# LPC5411x register map
Vendor: nxp.com; File version: 1.2
CPU: CM4 r0p1, little endian, MPU, FPU, VTOR, vendor SysTick, 3 interrupt priority bits
Registers are 32-bit, read-write, reset 0x0 unless marked. A register's access mark holds for its fields unless they carry their own. Offsets are from the block's base; [hi:lo] are bit positions; {n}, {i} and the like mark numbered series; 'fields as' and 'values as' point back to an identical list.

## SYSCON — LPC5411x System configuration (SYSCON)
Base 0x40000000
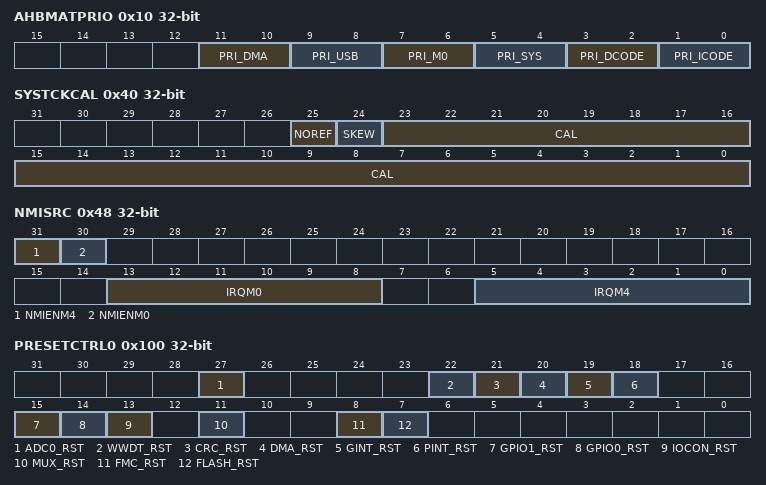
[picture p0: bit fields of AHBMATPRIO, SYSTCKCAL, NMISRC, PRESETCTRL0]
0x10 AHBMATPRIO — AHB multilayer matrix priority control
  [11:10] PRI_DMA — DMA controller priority.
  [9:8] PRI_USB — USB interface priority.
  [7:6] PRI_M0 — Cortex-M0+ bus priority. Present on selected devices.
  [5:4] PRI_SYS — Cortex M4 System bus priority.
  [3:2] PRI_DCODE — Cortex M4 D-Code bus priority.
  [1:0] PRI_ICODE — Cortex-M4 I-Code bus priority. Should typically be lower than PRI_DCODE for best operation.
0x40 SYSTCKCAL — System tick counter calibration
  [25] NOREF — Initial value for the Systick timer.
  [24] SKEW — Initial value for the Systick timer.
  [23:0] CAL — System tick timer calibration value.
0x48 NMISRC — NMI Source Select
  [31] NMIENM4 — Write a 1 to this bit to enable the Non-Maskable Interrupt (NMI) source selected by IRQM4.
  [30] NMIENM0 — Write a 1 to this bit to enable the Non-Maskable Interrupt (NMI) source selected by IRQM0. Present on selected devices.
  [13:8] IRQM0 — The IRQ number of the interrupt that acts as the Non-Maskable Interrupt (NMI) for the Cortex-M0+, if enabled by NMIENM0. Present on selected devices.
  [5:0] IRQM4 — The IRQ number of the interrupt that acts as the Non-Maskable Interrupt (NMI) for the Cortex-M4, if enabled by NMIENM4.
0x4C ASYNCAPBCTRL reset 0x1 — Asynchronous APB Control
  [0] ENABLE — Enables the asynchronous APB bridge and subsystem.
    0=DISABLED (Disabled. Asynchronous APB bridge is disabled.); 1=ENABLED (Enabled. Asynchronous APB bridge is enabled.)
0xC0 PIOPORCAP0 — POR captured value of port 0
  [31:0] PIOPORCAP ro — State of PIO0_31 through PIO0_0 at power-on reset
0xC4 PIOPORCAP1 — POR captured value of port 1
  [31:0] PIOPORCAP ro — State of PIO1_31 through PIO1_0 at power-on reset
0xD0 PIORESCAP0 — Reset captured value of port 0
  [31:0] PIORESCAP ro — State of PIO0_31 through PIO0_0 for resets other than POR.
0xD4 PIORESCAP1 — Reset captured value of port 1
  [31:0] PIORESCAP ro — State of PIO1_31 through PIO1_0 for resets other than POR.
0x100 PRESETCTRL0 — Peripheral reset control 0
  [27] ADC0_RST — ADC0 reset control. 0 = Clear reset to this function. 1 = Assert reset to this function.
  [22] WWDT_RST — Watchdog timer reset control. 0 = Clear reset to this function. 1 = Assert reset to this function.
  [21] CRC_RST — CRC generator reset control. 0 = Clear reset to this function. 1 = Assert reset to this function.
  [20] DMA_RST — DMA reset control. 0 = Clear reset to this function. 1 = Assert reset to this function.
  [19] GINT_RST — Grouped interrupt (GINT) reset control. 0 = Clear reset to this function. 1 = Assert reset to this function.
  [18] PINT_RST — Pin interrupt (PINT) reset control. 0 = Clear reset to this function. 1 = Assert reset to this function.
  [15] GPIO1_RST — GPIO1 reset control. 0 = Clear reset to this function. 1 = Assert reset to this function.
  [14] GPIO0_RST — GPIO0 reset control. 0 = Clear reset to this function. 1 = Assert reset to this function.
  [13] IOCON_RST — IOCON reset control. 0 = Clear reset to this function. 1 = Assert reset to this function.
  [11] MUX_RST — Input mux reset control. 0 = Clear reset to this function. 1 = Assert reset to this function.
  [8] FMC_RST — Flash accelerator reset control. Note that the FMC must not be reset while executing from flash, and must be reconfigured after reset. 0 = Clear reset to this function. 1 = Assert reset to this function.
  [7] FLASH_RST — Flash controller reset control. 0 = Clear reset to this function. 1 = Assert reset to this function.
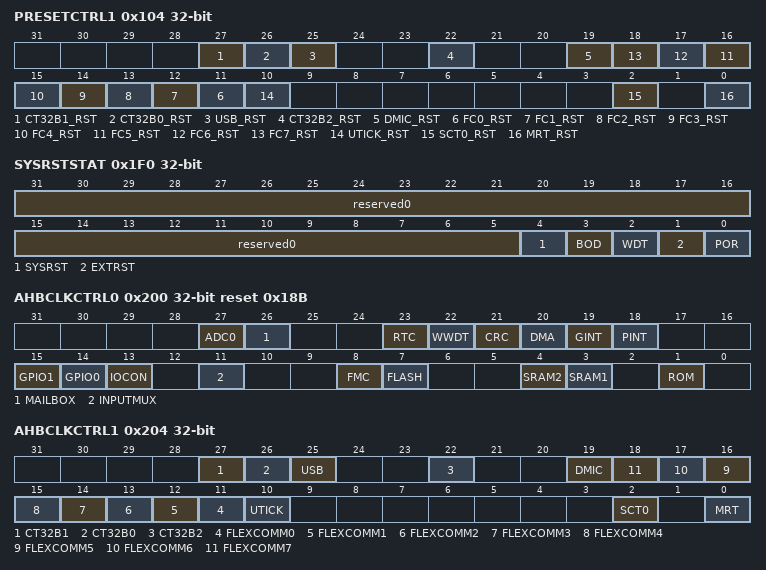
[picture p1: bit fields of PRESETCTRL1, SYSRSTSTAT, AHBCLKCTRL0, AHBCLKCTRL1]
0x104 PRESETCTRL1 — Peripheral reset control 1
  [27] CT32B1_RST — CT32B1 reset control. 0 = Clear reset to this function. 1 = Assert reset to this function.
  [26] CT32B0_RST — CT32B0 reset control. 0 = Clear reset to this function. 1 = Assert reset to this function.
  [25] USB_RST — USB reset control. 0 = Clear reset to this function. 1 = Assert reset to this function.
  [22] CT32B2_RST — CT32B2 reset control. 0 = Clear reset to this function. 1 = Assert reset to this function
  [19] DMIC_RST — Digital microphone interface reset control. 0 = Clear reset to this function. 1 = Assert reset to this function.
  [n+11] FC{n}_RST (n=0..7) — Flexcomm {n} reset control. 0 = Clear reset to this function. 1 = Assert reset to this function.
  [10] UTICK_RST — Micro-tick Timer reset control. 0 = Clear reset to this function. 1 = Assert reset to this function.
  [2] SCT0_RST — State configurable timer 0 (SCT0) reset control. 0 = Clear reset to this function. 1 = Assert reset to this function.
  [0] MRT_RST — Multi-rate timer (MRT) reset control. 0 = Clear reset to this function. 1 = Assert reset to this function.
0x120 PRESETCTRLSET0 reset not defined — Set bits in PRESETCTRL0
  [31:0] RST_SET0 wo — Writing ones to this register sets the corresponding bit or bits in the PRESETCTRL0 register, if they are implemented. Bits that do not correspond to defined bits in PRESETCTRL0 are reserved and only zeroes should be written to them.
0x124 PRESETCTRLSET1 reset not defined — Set bits in PRESETCTRL1
  [31:0] RST_SET1 wo — Writing ones to this register sets the corresponding bit or bits in the PRESETCTRL1 register, if they are implemented. Bits that do not correspond to defined bits in PRESETCTRL1 are reserved and only zeroes should be written to them.
0x140 PRESETCTRLCLR0 reset not defined — Clear bits in PRESETCTRL0
  [31:0] RST_CLR0 wo — Writing ones to this register clears the corresponding bit or bits in the PRESETCTRL0 register, if they are implemented. Bits that do not correspond to defined bits in PRESETCTRL0 are reserved and only zeroes should be written to them.
0x144 PRESETCTRLCLR1 reset not defined — Clear bits in PRESETCTRL1
  [31:0] RST_CLR1 wo — Writing ones to this register clears the corresponding bit or bits in the PRESETCTRL1 register, if they are implemented. Bits that do not correspond to defined bits in PRESETCTRL1 are reserved and only zeroes should be written to them.
0x1F0 SYSRSTSTAT (reset mask 0x1F) — System reset status register
  [31:5] reserved0 wo
  [4] SYSRST — Status of the software system reset
    0=NO_SYSTEM_RESET_DETECTED; 1=SYSTEM_RESET_DETECTED (System reset detected. Writing a one clears this reset.)
  [3] BOD — Status of the Brown-out detect reset
    0=NO_BOD_RESET_DETECTED; 1=BOD_RESET_DETECTED (BOD reset detected. Writing a one clears this reset.)
  [2] WDT — Status of the Watchdog reset
    0=NO_WDT_RESET_DETECTED; 1=WDT_RESET_DETECTED (WDT reset detected. Writing a one clears this reset.)
  [1] EXTRST — Status of the external RESET pin. External reset status
    0=NO_RESET_DETECTED (No reset event detected.); 1=RESET_DETECTED (Reset detected. Writing a one clears this reset.)
  [0] POR — POR reset status
    0=NO_POR_DETECTED; 1=POR_DETECTED (POR detected. Writing a one clears this reset.)
0x200 AHBCLKCTRL0 reset 0x18B — AHB Clock control 0
  [27] ADC0 — Enables the clock for the ADC0 register interface. 0 = Disable; 1 = Enable.
  [26] MAILBOX — Enables the clock for the Mailbox. 0 = Disable; 1 = Enable. Present on selected devices
  [23] RTC — Enables the bus clock for the RTC. 0 = Disable; 1 = Enable.
  [22] WWDT — Enables the clock for the Watchdog Timer. 0 = Disable; 1 = Enable.
  [21] CRC — Enables the clock for the CRC engine. 0 = Disable; 1 = Enable.
  [20] DMA — Enables the clock for the DMA controller. 0 = Disable; 1 = Enable.
  [19] GINT — Enables the clock for the grouped pin interrupt block. 0 = Disable; 1 = Enable.
  [18] PINT — Enables the clock for the pin interrupt block.0 = Disable; 1 = Enable.
  [15] GPIO1 — Enables the clock for the GPIO1 port registers. 0 = Disable; 1 = Enable.
  [14] GPIO0 — Enables the clock for the GPIO0 port registers. 0 = Disable; 1 = Enable.
  [13] IOCON — Enables the clock for the IOCON block. 0 = Disable; 1 = Enable.
  [11] INPUTMUX — Enables the clock for the input muxes. 0 = Disable; 1 = Enable.
  [8] FMC — Enables the clock for the Flash accelerator. 0 = Disable; 1 = Enable. This clock is needed if the flash is being read.
  [7] FLASH — Enables the clock for the flash controller. 0 = Disable; 1 = Enable. This clock is needed for flash programming, not for flash read.
  [4] SRAM2 — Enables the clock for SRAM2. 0 = Disable; 1 = Enable.
  [3] SRAM1 — Enables the clock for SRAM1. 0 = Disable; 1 = Enable.
  [1] ROM — Enables the clock for the Boot ROM. 0 = Disable; 1 = Enable.
0x204 AHBCLKCTRL1 — AHB Clock control 1
  [27] CT32B1 — Enables the clock for timer CT32B1. 0 = Disable; 1 = Enable.
  [26] CT32B0 — Enables the clock for timer CT32B0. 0 = Disable; 1 = Enable.
  [25] USB — Enables the clock for the USB interface. 0 = Disable; 1 = Enable.
  [22] CT32B2 — Enables the clock for CT32B 2. 0 = Disable; 1 = Enable.
  [19] DMIC — Enables the clock for the digital microphone interface. 0 = Disable; 1 = Enable.
  [n+11] FLEXCOMM{n} (n=0..7) — Enables the clock for Flexcomm {n}. 0 = Disable; 1 = Enable.
  [10] UTICK — Enables the clock for the Micro-tick Timer. 0 = Disable; 1 = Enable.
  [2] SCT0 — Enables the clock for SCT0. 0 = Disable; 1 = Enable.
  [0] MRT — Enables the clock for the Multi-Rate Timer. 0 = Disable; 1 = Enable.
0x220 AHBCLKCTRLSET0 reset not defined — Set bits in AHBCLKCTRL0
  [31:0] CLK_SET0 wo — Writing ones to this register sets the corresponding bit or bits in the AHBCLKCTRL0 register, if they are implemented. Bits that do not correspond to defined bits in AHBCLKCTRL0 are reserved and only zeroes should be written to them.
0x224 AHBCLKCTRLSET1 reset not defined — Set bits in AHBCLKCTRL1
  [31:0] CLK_SET1 wo — Writing ones to this register sets the corresponding bit or bits in the AHBCLKCTRL1 register, if they are implemented. Bits that do not correspond to defined bits in AHBCLKCTRL1 are reserved and only zeroes should be written to them.
0x240 AHBCLKCTRLCLR0 reset not defined — Clear bits in AHBCLKCTRL0
  [31:0] CLK_CLR0 wo — Writing ones to this register clears the corresponding bit or bits in the AHBCLKCTRL0 register, if they are implemented. Bits that do not correspond to defined bits in AHBCLKCTRL0 are reserved and only zeroes should be written to them.
0x244 AHBCLKCTRLCLR1 reset not defined — Clear bits in AHBCLKCTRL1
  [31:0] CLK_CLR1 wo — Writing ones to this register clears the corresponding bit or bits in the AHBCLKCTRL1 register, if they are implemented. Bits that do not correspond to defined bits in AHBCLKCTRL1 are reserved and only zeroes should be written to them.
0x280 MAINCLKSELA — Main clock source select A
  [1:0] SEL — Clock source for main clock source selector A
    0=FRO_12_MHZ (FRO 12 MHz (fro_12m)); 1=CLKIN (CLKIN (clk_in)); 2=WATCHDOG_OSCILLATOR (Watchdog oscillator (wdt_clk)); 3=FRO_HF (FRO 96 or 48 MHz (fro_hf))
0x284 MAINCLKSELB — Main clock source select B
  [1:0] SEL — Clock source for main clock source selector B. Selects the clock source for the main clock.
    0=MAINCLKSELA (MAINCLKSELA. Use the clock source selected in MAINCLKSELA register.); 2=SYSTEM_PLL_OUTPUT (System PLL output (pll_clk)); 3=RTC_OSC_OUTPUT (RTC oscillator 32 kHz output (32k_clk))
0x288 CLKOUTSELA reset 0x7 — CLKOUT clock source select A
  [2:0] SEL — CLKOUT clock source selection
    0=MAIN_CLOCK (Main clock (main_clk)); 1=CLKIN (CLKIN (clk_in)); 2=WATCHDOG_OSCILLATOR (Watchdog oscillator (wdt_clk)); 3=FRO_HF (FRO 96 or 48 MHz (fro_hf)); 4=SYSTEM_PLL_OUTPUT (PLL output (pll_clk)); 5=FRO_12_MHZ (FRO 12 MHz (fro_12m)); 6=RTC_OSC_OUTPUT (RTC oscillator 32 kHz output (32k_clk)); 7=NONE (None, this may be selected in order to reduce power when no output is needed.)
0x290 SYSPLLCLKSEL reset 0x7 — PLL clock source select
  [2:0] SEL — System PLL clock source selection
    0=FRO_12_MHZ (FRO 12 MHz (fro_12m)); 1=CLKIN (CLKIN (clk_in)); 2=WATCHDOG_OSCILLATOR (Watchdog oscillator (wdt_clk)); 3=RTC_32_KHZ_CLOCK (RTC 32 kHz clock (32k_clk)); 7=NONE (None, this may be selected in order to reduce power when no output is needed.)
0x2A4 ADCCLKSEL reset 0x7 — ADC clock source select
  [2:0] SEL — ADC clock source selection
    0=MAIN_CLOCK (Main clock (main_clk)); 1=SYSTEM_PLL_OUTPUT (System PLL output (pll_clk)); 2=FRO_HF (FRO 96 or 48 MHz (fro_hf)); 7=NONE (None, this may be selected in order to reduce power when no output is needed.)
0x2A8 USBCLKSEL reset 0x7 — USB clock source select
  [2:0] SEL — USB device clock source selection
    0=FRO_HF (FRO 96 or 48 MHz (fro_hf)); 1=SYSTEM_PLL_OUTPUT (System PLL output (pll_clk)); 2=MAIN_CLOCK (Main clock (main_clk)); 7=NONE (None, this may be selected in order to reduce power when no output is needed.)
{0x2B0+4i} FXCOMCLKSEL[{i}] (i=0..7) reset 0x7 — Flexcomm 0 clock source select
  [2:0] SEL — Flexcomm clock source selection. One per Flexcomm.
    0=FRO_12_MHZ (FRO 12 MHz (fro_12m)); 1=FRO_HF (FRO 96 or 48 MHz (fro_hf)); 2=SYSTEM_PLL_OUTPUT (System PLL output (pll_clk)); 3=MCLK_INPUT (MCLK pin input, when selected in IOCON (mclk_in)); 4=FRG_CLOCK_OUTPUT (FRG clock, the output of the fractional rate generator (frg_clk)); 7=NONE (None, this may be selected in order to reduce power when no output is needed.)
0x2E0 MCLKCLKSEL reset 0x7 — MCLK clock source select
  [2:0] SEL — MCLK source select. This may be used by Flexcomms that support I2S, and/or by the digital microphone subsystem.
    values as USBCLKSEL.SEL
0x2E8 FRGCLKSEL reset 0x7 — Fractional Rate Generator clock source select
  [2:0] SEL — Fractional Rate Generator clock source select.
    0=MAIN_CLOCK (Main clock (main_clk)); 1=SYSTEM_PLL_OUTPUT (System PLL output (pll_clk)); 2=FRO_12_MHZ (FRO 12 MHz (fro_12m)); 3=FRO_HF (FRO 96 or 48 MHz (fro_hf)); 7=NONE (None, this may be selected in order to reduce power when no output is needed.)
0x2EC DMICCLKSEL reset 0x7 — Digital microphone (D-Mic) subsystem clock select
  [2:0] SEL — D-Mic subsystem clock source select.
    0=FRO_12_MHZ (FRO 12 MHz (fro_12m)); 1=FRO_HF (FRO 96 or 48 MHz (fro_hf)); 2=SYSTEM_PLL_OUTPUT (System PLL output (pll_clk)); 3=MCLK_INPUT (MCLK pin input, when selected in IOCON (mclk_in)); 4=MAIN_CLOCK (Main clock (main_clk)); 5=WATCHDOG_OSCILLATOR (Watchdog oscillator (wdt_clk)); 7=NONE (None, this may be selected in order to reduce power when no output is needed.)
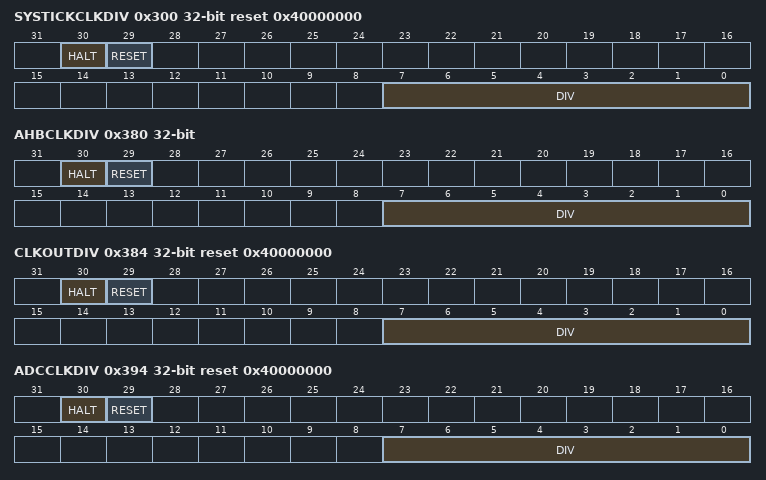
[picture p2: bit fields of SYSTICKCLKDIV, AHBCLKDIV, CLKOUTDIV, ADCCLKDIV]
0x300 SYSTICKCLKDIV reset 0x40000000 — SYSTICK clock divider
  [30] HALT — Halts the divider counter. The intent is to allow the divider clock source to be changed without the risk of a glitch at the output.
  [29] RESET — Resets the divider counter. Can be used to make sure a new divider value is used right away rather than completing the previous count.
  [7:0] DIV — Clock divider value. 0: Divide by 1 up to 255: Divide by 256.
0x380 AHBCLKDIV — AHB clock divider
  fields as SYSTICKCLKDIV
0x384 CLKOUTDIV reset 0x40000000 — CLKOUT clock divider
  fields as SYSTICKCLKDIV
0x394 ADCCLKDIV reset 0x40000000 — ADC clock divider
  fields as SYSTICKCLKDIV
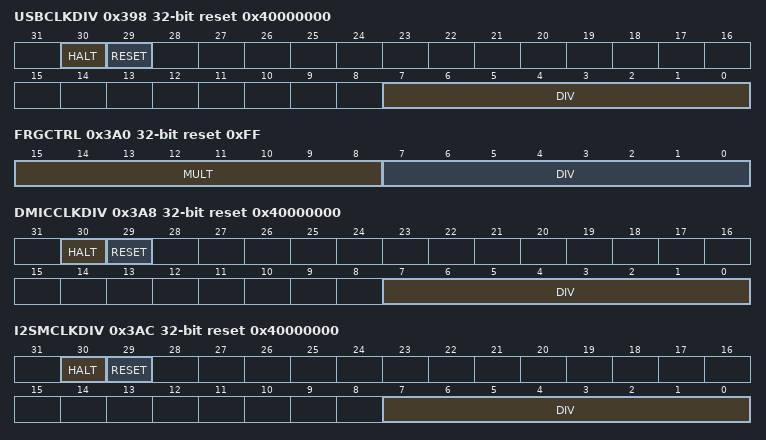
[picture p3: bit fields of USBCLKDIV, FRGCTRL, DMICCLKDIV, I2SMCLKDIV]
0x398 USBCLKDIV reset 0x40000000 — USB clock divider
  fields as SYSTICKCLKDIV
0x3A0 FRGCTRL reset 0xFF — Fractional rate divider
  [15:8] MULT — Numerator of the fractional divider. MULT is equal to the programmed value.
  [7:0] DIV — Denominator of the fractional divider. DIV is equal to the programmed value +1. Always set to 0xFF to use with the fractional baud rate generator.
0x3A8 DMICCLKDIV reset 0x40000000 — DMIC clock divider
  fields as SYSTICKCLKDIV
0x3AC I2SMCLKDIV reset 0x40000000 — I2S MCLK clock divider
  fields as SYSTICKCLKDIV
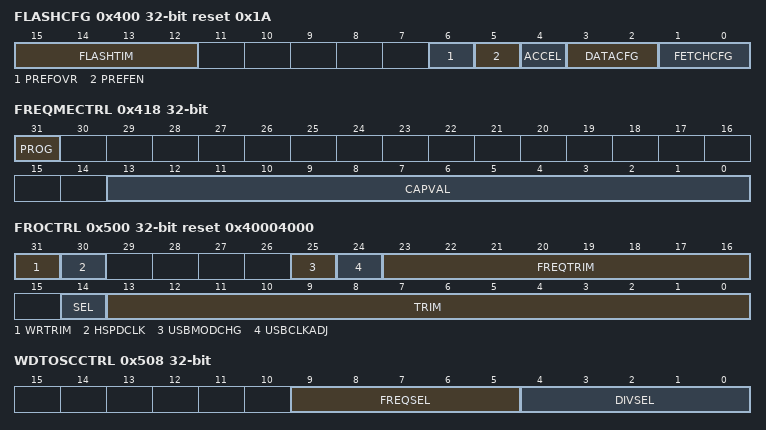
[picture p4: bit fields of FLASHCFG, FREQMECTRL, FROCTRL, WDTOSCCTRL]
0x400 FLASHCFG reset 0x1A — Flash wait states configuration
  [15:12] FLASHTIM — Flash memory access time. The number of system clocks used for flash accesses is equal to FLASHTIM +1.
    0=N_1_CLOCK_CYCLE (1 system clock flash access time (for system clock rates up to 12 MHz).); 1=N_2_CLOCK_CYCLES (2 system clocks flash access time (for system clock rates up to 30 MHz).); 2=N_3_CLOCK_CYCLES (3 system clocks flash access time (for system clock rates up to 60 MHz).); 3=N_4_CLOCK_CYCLES (4 system clocks flash access time (for system clock rates up to 85 MHz).); 4=N_5_CLOCK_CYCLES (5 system clocks flash access time (for system clock rates up to 100 MHz).)
  [6] PREFOVR — Prefetch override. This bit only applies when PREFEN = 1 and a buffered instruction is completing for which the next flash line is not already buffered or being prefetched.
    0=PREFETCH_COMPLETED (Any previously initiated prefetch will be completed.); 1=PREFETCH_ABORT (Any previously initiated prefetch will be aborted, and the next flash line following the current execution address will be prefetched if not already buffered.)
  [5] PREFEN — Prefetch enable.
    0=NO_PREFETCH (No instruction prefetch is performed.); 1=PREFETCH (If the FETCHCFG field is not 0, the next flash line following the current execution address is automatically prefetched if it is not already buffered.)
  [4] ACCEL — Acceleration enable.
    0=DISABLED (Flash acceleration is disabled. Every flash read (including those fulfilled from a buffer) takes FLASHTIM + 1 system clocks. This allows more determinism at a cost of performance.); 1=ENABLED (Flash acceleration is enabled. Performance is enhanced, dependent on other FLASHCFG settings.)
  [3:2] DATACFG — Data read configuration. This field determines how flash accelerator buffers are used for data accesses.
    0=NOT_BUFFERED (Data accesses from flash are not buffered. Every data access from the CPU results in a read of the flash memory.); 1=ONE_BUFFER (One buffer is used for all data accesses.); 2=ALL_BUFFERS (All buffers may be used for data accesses.)
  [1:0] FETCHCFG — Instruction fetch configuration. This field determines how flash accelerator buffers are used for instruction fetches.
    0=NO_BUFFER (Instruction fetches from flash are not buffered. Every fetch request from the CPU results in a read of the flash memory. This setting may use significantly more power than when buffering is enabled.); 1=ONE_BUFFER (One buffer is used for all instruction fetches.); 2=ALL_BUFFERS (All buffers may be used for instruction fetches.)
0x40C USBCLKCTRL — USB clock control
  [1] POL_CLK — USB_NEED_CLK polarity for triggering the USB wake-up interrupt
    0=FALLING_EDGE (Falling edge of the USB_NEED_CLK triggers the USB wake-up (default).); 1=RISING_EDGE (Rising edge of the USB_NEED_CLK triggers the USB wake-up.)
0x410 USBCLKSTAT — USB clock status
  [0] NEED_CLKST — USB_NEED_CLK signal status
    0=LOW; 1=HIGH
0x418 FREQMECTRL — Frequency measure register
  [31] PROG — Set this bit to one to initiate a frequency measurement cycle. Hardware clears this bit when the measurement cycle has completed and there is valid capture data in the CAPVAL field (bits 13:0).
  [13:0] CAPVAL — Stores the capture result which is used to calculate the frequency of the target clock. This field is read-only.
0x420 MCLKIO — MCLK input/output control
  [0] DIR — MCLK direction control.
    0=INPUT (The MCLK function is an input.); 1=OUTPUT (The MCLK function is an output.)
0x500 FROCTRL reset 0x40004000 — FRO oscillator control
  [31] WRTRIM — Write Trim value. Must be written to 1 to modify the SEL or TRIM fields, during the same write. This bit always reads as 0.
  [30] HSPDCLK — High speed clock disable. Allows disabling the highs-speed FRO output if it is not needed.
    0=DISABLED (The high-speed FRO output is disabled.); 1=ENABLED (The selected high-speed FRO output (48 MHz or 96 MHz) is enabled.)
  [25] USBMODCHG — USB Mode value Change flag. When 1, indicates that the USB trim is currently being updated (or is still starting up) and software should wait to read FREQTRIM. Update occurs at most once per millisecond.
  [24] USBCLKADJ — USB clock adjust mode.
    0=NORMAL (Normal operation.); 1=AUTO_USB_ADJUST (Automatic USB rate adjustment mode. If the USB FS device peripheral is enabled and connected to a USB host, it provides clock adjustment information to the FRO based on SOF packets. USB rate adjustment requires a number of cycles to take place. the USBMODCHG bit (see below) indicates when initial adjustment is complete, and when later adjustments are in progress. software must not alter TRIM and FREQTRIM while USBCLKADJ = 1. see USBCLKADJ usage notes below this table.)
  [23:16] FREQTRIM — Frequency trim. Boot code configures this to a device-specific factory trim value for the 96 MHz FRO. If USBCLKADJ = 1, this field is read-only and provides the value resulting from USB rate adjustment. See the USBMODCFG flag regarding reading this field. Application code may adjust this field when USBCLKADJ = 0. A single step of FREQTRIM is roughly equivalent to 0.1% of the selected FRO frequency.
  [14] SEL — Select the fro_hf output frequency. This bit can only be changed by software when the WRTRIM bit = 1. Note that the factory trim values are for the 96 MHz FRO only.
    0=FRQ_48_MHZ (48 MHz); 1=FRQ_96_MHZ (96 MHz)
  [13:0] TRIM — This value is factory trimmed to account for bias and temperature compensation. The value should not be changed by software. Also see the WRTRIM bit description.
0x508 WDTOSCCTRL — Watchdog oscillator control
  [9:5] FREQSEL — Frequency select. Selects the frequency of the oscillator. 0x00 = invalid setting when watchdog oscillator is running 0x01 = 0.4 MHz 0x02 = 0.6 MHz 0x03 = 0.75 MHz 0x04 = 0.9 MHz 0x05 = 1.0 MHz 0x06 = 1.2 MHz 0x07 = 1.3 MHz 0x08 = 1.4 MHz 0x09 = 1.5 MHz 0x0A = 1.6 MHz 0x0B = 1.7 MHz 0x0C = 1.8 MHz 0x0D = 1.9 MHz 0x0E = 2.0 MHz 0x0F = 2.05 MHz 0x10 = 2.1 MHz 0x11 = 2.2 MHz 0x12 = 2.25 MHz 0x13 = 2.3 MHz 0x14 = 2.4 MHz 0x15 = 2.45 MHz 0x16 = 2.5 MHz 0x17 = 2.6 MHz 0x18 = 2.65 MHz 0x19 = 2.7 MHz 0x1A = 2.8 MHz 0x1B = 2.85 MHz 0x1C = 2.9 MHz 0x1D = 2.95 MHz 0x1E = 3.0 MHz 0x1F = 3.05 MHz
  [4:0] DIVSEL — Divider select. Selects the value of the divider that adjusts the output of the oscillator. 0x00 = divide by 2 0x01 = divide by 4 0x02 = divide by 6 up to 0x1E = divide by 62 0x1F = divide by 64
0x50C RTCOSCCTRL reset 0x1 — RTC oscillator 32 kHz output control
  [0] EN — RTC 32 kHz clock enable.
    0=DISABLED (Disabled. RTC clock off.); 1=ENABLED (Enabled. RTC clock on.)
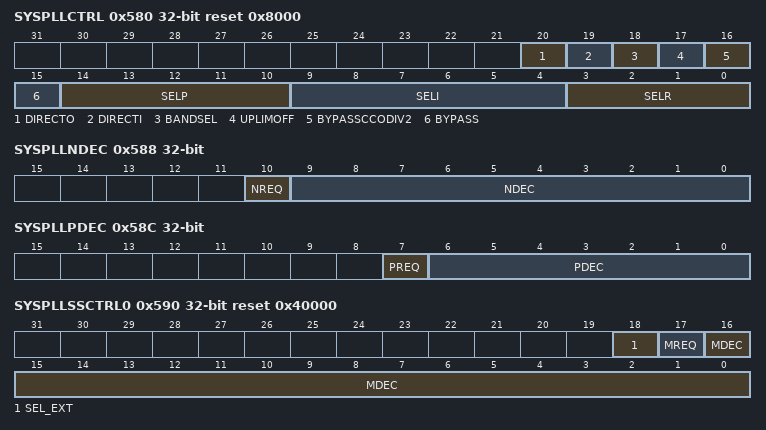
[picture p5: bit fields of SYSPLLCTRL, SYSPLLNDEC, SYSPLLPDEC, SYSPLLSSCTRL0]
0x580 SYSPLLCTRL reset 0x8000 — PLL control
  [20] DIRECTO — PLL0 direct output enable.
    0=DISABLED (Disabled. The PLL output divider (P divider) is used to create the PLL output.); 1=ENABLED (Enabled. The PLL output divider (P divider) is bypassed, the PLL CCO output is used as the PLL output.)
  [19] DIRECTI — PLL0 direct input enable
    0=DISABLED (Disabled. The PLL input divider (N divider) output is used to drive the PLL CCO.); 1=ENABLED (Enabled. The PLL input divider (N divider) is bypassed. the PLL input clock is used directly to drive the PLL CCO input.)
  [18] BANDSEL — PLL filter control. Set this bit to one when the spread spectrum controller is disabled or at low frequencies. For spread spectrum mode: SEL_EXT = 0, BANDSEL = 0, and UPLIMOFF = 1.
    0=SSCG_CONTROL (SSCG control. The PLL filter uses the parameters derived from the spread spectrum controller.); 1=MDEC_CONTROL (MDEC control. The PLL filter uses the programmable fields SELP, SELR, and SELI in this register to control the filter constants.)
  [17] UPLIMOFF — Disable upper frequency limiter.
    0=NORMAL (Normal mode.); 1=DISABLED (Upper frequency limiter disabled.)
  [16] BYPASSCCODIV2 — Bypass feedback clock divide by 2.
    0=DIVIDE_BY_2 (Divide by 2. The CCO feedback clock is divided by 2 in addition to the programmed M divide.); 1=BYPASS (Bypass. The CCO feedback clock is divided only by the programmed M divide.)
  [15] BYPASS — PLL bypass control.
    0=DISABLED (Bypass disabled. PLL CCO is sent to the PLL post-dividers.); 1=ENABLED (Bypass enabled. PLL input clock is sent to the PLL post-dividers (default).)
  [14:10] SELP — Bandwidth select P value
  [9:4] SELI — Bandwidth select I value.
  [3:0] SELR — Bandwidth select R value
0x584 SYSPLLSTAT — PLL status
  [0] LOCK ro — PLL0 lock indicator
0x588 SYSPLLNDEC — PLL N decoder
  [10] NREQ — NDEC reload request. When a 1 is written to this bit, the NDEC value is loaded into the PLL. Must be cleared by software for any subsequent load, or the PLL can be powered down and back up via the PDEN_SYS_PLL bit in the PDRUNCFG register if the NDEC value is changed.
  [9:0] NDEC — Decoded N-divider coefficient value.
0x58C SYSPLLPDEC — PLL P decoder
  [7] PREQ — PDEC reload request. When a 1 is written to this bit, the PDEC value is loaded into the PLL. Must be cleared by software for any subsequent load, or the PLL can be powered down and back up via the PDEN_SYS_PLL bit in the PDRUNCFG register if the PDEC value is changed.
  [6:0] PDEC — Decoded P-divider coefficient value.
0x590 SYSPLLSSCTRL0 reset 0x40000 — PLL spread spectrum control 0
  [18] SEL_EXT — Select spread spectrum mode. Selects the source of the feedback divider value. For normal mode, this must be the value from the MDEC field in this register. For spread spectrum mode: SEL_EXT = 0, BANDSEL = 0, and UPLIMOFF = 1.
  [17] MREQ — MDEC reload request. When a 1 is written to this bit, the MDEC value is loaded into the PLL. Must be cleared by software for any subsequent load, or the PLL can be powered down and back up via the PDEN_SYS_PLL bit in the PDRUNCFG register if the MDEC value is changed.
  [16:0] MDEC — Decoded M-divider coefficient value.
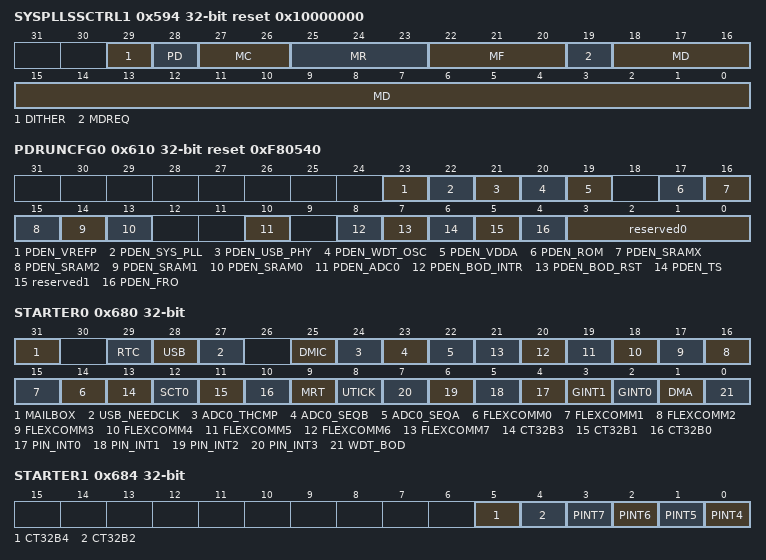
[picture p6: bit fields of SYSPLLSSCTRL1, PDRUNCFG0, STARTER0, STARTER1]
0x594 SYSPLLSSCTRL1 reset 0x10000000 — PLL spread spectrum control 1
  [29] DITHER — Select modulation frequency.
    0=FIXED (Fixed. Fixed modulation frequency.); 1=DITHER (Dither. Randomly dither between two modulation frequencies.)
  [28] PD — Spread spectrum power-down.
    0=ENABLED (Enabled. Spread spectrum controller is enabled); 1=DISABLED (Disabled. Spread spectrum controller is disabled.)
  [27:26] MC — Modulation waveform control. 0 = no compensation. Compensation for low pass filtering of the PLL to get a triangular modulation at the output of the PLL, giving a flat frequency spectrum. 0b00 =&gt; no compensation 0b10 =&gt; recommended setting 0b11 =&gt; max. compensation
  [25:23] MR — Programmable frequency modulation depth. 0 = no spread. _fmodpk-pk = Fref x k/Fcco = k/MDdec 0b000 =&gt; k = 0 (no spread spectrum) 0b001 =&gt; k _ 1 0b010 =&gt; k _ 1.5 0b011 =&gt; k _ 2 0b100 =&gt; k _ 3 0b101 =&gt; k _ 4 0b110 =&gt; k _ 6 0b111 =&gt; k _ 8
  [22:20] MF — Programmable modulation frequency fm = Fref/Nss with Fref = Fin/N 0b000 =&gt; Nss = 512 (fm _ 3.9 - 7.8 kHz) 0b001 =&gt; Nss _ 384 (fm _ 5.2 - 10.4 kHz) 0b010 =&gt; Nss = 256 (fm _ 7.8 - 15.6 kHz) 0b011 =&gt; Nss = 128 (fm _ 15.6 - 31.3 kHz) 0b100 =&gt; Nss = 64 (fm _ 32.3 - 64.5 kHz) 0b101 =&gt; Nss = 32 (fm _ 62.5- 125 kHz) 0b110 =&gt; Nss _ 24 (fm _ 83.3- 166.6 kHz) 0b111 =&gt; Nss = 16 (fm _ 125- 250 kHz)
  [19] MDREQ — MD reload request. When a 1 is written to this bit, the MD value is loaded into the PLL. This bit is cleared when the load is complete
  [18:0] MD — M- divider value with fraction. MD[18:11]: integer portion of the feedback divider value. MD[10:0]: fractional portion of the feedback divider value. In fractional mode, fcco = (2 - BYPASSCCODIV2) x (MD x 2^-11) x Fref
0x610 PDRUNCFG0 reset 0xF80540 (reset mask 0xFBE5D0) — Power configuration register 0
  [23] PDEN_VREFP — Vrefp to the ADC, must be enabled for the ADC to work. Also see bit 19. 0 = Powered; 1 = Powered down.
  [22] PDEN_SYS_PLL — PLL0. 0 = Powered; 1 = Powered down.
  [21] PDEN_USB_PHY — USB pin interface. 0 = Powered; 1 = Powered down.
  [20] PDEN_WDT_OSC — Watchdog oscillator. 0 = Powered; 1 = Powered down.
  [19] PDEN_VDDA — Vdda to the ADC, must be enabled for the ADC to work. Also see bit 23. 0 = Powered; 1 = Powered down.
  [17] PDEN_ROM — ROM. 0 = Powered; 1 = Powered down.
  [16] PDEN_SRAMX — SRAMX. 0 = Powered; 1 = Powered down.
  [15] PDEN_SRAM2 — SRAM2. 0 = Powered; 1 = Powered down.
  [14] PDEN_SRAM1 — SRAM1. 0 = Powered; 1 = Powered down.
  [13] PDEN_SRAM0 — SRAM0. 0 = Powered; 1 = Powered down.
  [10] PDEN_ADC0 — ADC0. 0 = Powered; 1 = Powered down.
  [8] PDEN_BOD_INTR — Brown-out Detect interrupt. 0 = Powered; 1 = Powered down.
  [7] PDEN_BOD_RST — Brown-out Detect reset. 0 = Powered; 1 = Powered down.
  [6] PDEN_TS — Temp sensor. 0 = Powered; 1 = Powered down.
  [5] reserved1 wo
  [4] PDEN_FRO — FRO oscillator. 0 = Powered; 1 = Powered down.
  [3:0] reserved0 wo
0x620 PDRUNCFGSET0 reset not defined — Set bits in PDRUNCFG0
  [31:0] PD_SET wo — Writing ones to this register sets the corresponding bit or bits in the PDRUNCFG register, if they are implemented. Bits that do not correspond to defined bits in PDRUNCFG are reserved and only zeroes should be written to them.
0x630 PDRUNCFGCLR0 reset not defined — Clear bits in PDRUNCFG0
  [31:0] PD_CLR wo — Writing ones to this register clears the corresponding bit or bits in the PDRUNCFG register, if they are implemented. Bits that do not correspond to defined bits in PDRUNCFG are reserved and only zeroes should be written to them.
0x680 STARTER0 — Start logic 0 wake-up enable register
  [31] MAILBOX — Mailbox interrupt wake-up. 0 = Wake-up disabled. 1 = Wake-up enabled.At least one CPU must be running in order for a mailbox interrupt to occur. Present on selected devices.
  [29] RTC — RTC interrupt alarm and wake-up timer. 0 = Wake-up disabled. 1 = Wake-up enabled.
  [28] USB — USB function interrupt wake-up. 0 = Wake-up disabled. 1 = Wake-up enabled.
  [27] USB_NEEDCLK — USB activity interrupt wake-up. 0 = Wake-up disabled. 1 = Wake-up enabled.
  [25] DMIC — Digital microphone interrupt wake-up. 0 = Wake-up disabled. 1 = Wake-up enabled.
  [24] ADC0_THCMP — ADC0 threshold and error interrupt wake-up. 0 = Wake-up disabled. 1 = Wake-up enabled.Typically used in sleep mode only since the peripheral clock must be running for it to function.
  [23] ADC0_SEQB — ADC0 sequence B interrupt wake-up. 0 = Wake-up disabled. 1 = Wake-up enabled.Typically used in sleep mode only since the peripheral clock must be running for it to function.
  [22] ADC0_SEQA — ADC0 sequence A interrupt wake-up. 0 = Wake-up disabled. 1 = Wake-up enabled.Typically used in sleep mode only since the peripheral clock must be running for it to function.
  [n+14] FLEXCOMM{n} (n=0..7) — Flexcomm{n} peripheral interrupt wake-up. 0 = Wake-up disabled. 1 = Wake-up enabled.
  [13] CT32B3 — Standard counter/timer CT32B3 wake-up. 0 = Wake-up disabled. 1 = Wake-up enabled.Typically used in sleep mode only since the peripheral clock must be running for it to function.
  [12] SCT0 — SCT0 wake-up. 0 = Wake-up disabled. 1 = Wake-up enabled.Typically used in sleep mode only since the peripheral clock must be running for it to function.
  [11] CT32B1 — Standard counter/timer CT32B1 wake-up. 0 = Wake-up disabled. 1 = Wake-up enabled.Typically used in sleep mode only since the peripheral clock must be running for it to function.
  [10] CT32B0 — Standard counter/timer CT32B0 wake-up. 0 = Wake-up disabled. 1 = Wake-up enabled.Typically used in sleep mode only since the peripheral clock must be running for it to function.
  [9] MRT — Multi-Rate Timer wake-up. 0 = Wake-up disabled. 1 = Wake-up enabled. Typically used in sleep mode only since the peripheral clock must be running for it to function.
  [8] UTICK — Micro-tick Timer wake-up. 0 = Wake-up disabled. 1 = Wake-up enabled.
  [n+4] PIN_INT{n} (n=0..3) — GPIO pin interrupt {n} wake-up. 0 = Wake-up disabled. 1 = Wake-up enabled. Not for pattern match.
  [3] GINT1 — Group interrupt 1 wake-up. 0 = Wake-up disabled. 1 = Wake-up enabled.
  [2] GINT0 — Group interrupt 0 wake-up. 0 = Wake-up disabled. 1 = Wake-up enabled.
  [1] DMA — DMA wake-up. 0 = Wake-up disabled. 1 = Wake-up enabled. Typically used in sleep mode only since the peripheral clock must be running for it to function.
  [0] WDT_BOD — WWDT and BOD interrupt wake-up. 0 = Wake-up disabled. 1 = Wake-up enabled.
0x684 STARTER1 — Start logic 1 wake-up enable register
  [5] CT32B4 — Standard counter/timer CT32B4 wake-up. 0 = Wake-up disabled. 1 = Wake-up enabled.Typically used in sleep mode only since the peripheral clock must be running for it to function.
  [4] CT32B2 — Standard counter/timer CT32B2 wake-up. 0 = Wake-up disabled. 1 = Wake-up enabled.Typically used in sleep mode only since the peripheral clock must be running for it to function.
  [n-4] PINT{n} (n=4..7) — GPIO pin interrupt {n} wake-up. 0 = Wake-up disabled. 1 = Wake-up enabled. Not for pattern match.
0x6A0 STARTERSET0 reset not defined — Set bits in STARTER0
  [31:0] START_SET0 wo — Writing ones to this register sets the corresponding bit or bits in the STARTER0 register, if they are implemented. Bits that do not correspond to defined bits in STARTER0 are reserved and only zeroes should be written to them.
0x6A4 STARTERSET1 reset not defined — Set bits in STARTER1
  [31:0] START_SET1 wo — Writing ones to this register sets the corresponding bit or bits in the STARTER1 register, if they are implemented. Bits that do not correspond to defined bits in STARTER1 are reserved and only zeroes should be written to them.
0x6C0 STARTERCLR0 reset not defined — Clear bits in STARTER0
  [31:0] START_CLR0 wo — Writing ones to this register clears the corresponding bit or bits in the STARTER0 register, if they are implemented. Bits that do not correspond to defined bits in STARTER0 are reserved and only zeroes should be written to them.
0x6C4 STARTERCLR1 reset not defined — Clear bits in STARTER1
  [31:0] START_CLR1 wo — Writing ones to this register clears the corresponding bit or bits in the STARTER1 register, if they are implemented. Bits that do not correspond to defined bits in STARTER1 are reserved and only zeroes should be written to them.
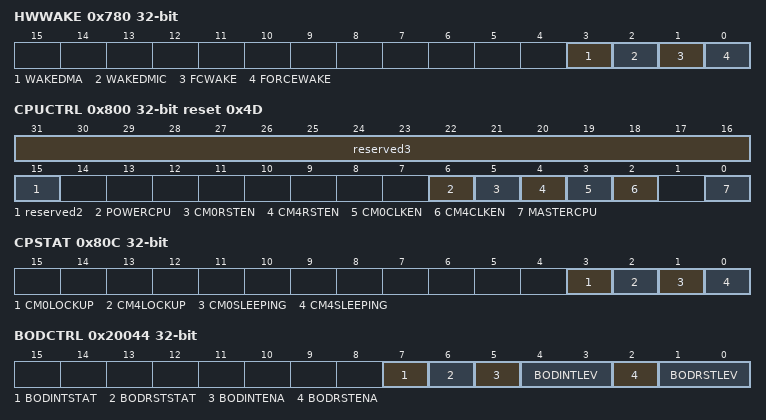
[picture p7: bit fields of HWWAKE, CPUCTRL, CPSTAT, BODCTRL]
0x780 HWWAKE — Configures special cases of hardware wake-up
  [3] WAKEDMA — Wake for DMA. When 1, DMA being busy will cause peripheral clocking to remain running until DMA completes. This is generally used in conjunction with bit 1 and/or 2 in order to prevent peripheral clocking from being shut down as soon as the cause of wake-up is cleared, but before DMA has completed its related activity.
  [2] WAKEDMIC — Wake for Digital Microphone. When 1, the digital microphone input FIFO reaching the level specified by TRIGLVL of either channel will cause peripheral clocking to wake up temporarily while the related status is asserted.
  [1] FCWAKE — Wake for Flexcomms. When 1, any Flexcomm FIFO reaching the level specified by its own TXLVL will cause peripheral clocking to wake up temporarily while the related status is asserted.
  [0] FORCEWAKE — Force peripheral clocking to stay on during Deep Sleep and Power-down modes. When 1, clocking to peripherals is prevented from being shut down when the CPU enters Deep Sleep and Power-down modes. This is intended to allow a coprocessor to continue operating while the main CPU(s) are shut down.
0x800 CPUCTRL reset 0x4D (reset mask 0x7D) — CPU Control for multiple processors
  [31:16] reserved3 wo — Must be written as 0xC0C4 for the write to have an effect.
  [15] reserved2 wo — Must be written as a 1.
  [6] POWERCPU — Identifies the owner of reduced power mode control: which CPU can cause the device to enter Deep Sleep, Power-down, and Deep Power-down modes.
    0=M0PL (M0+. Cortex-M0+ is the owner of reduced power mode control.); 1=M4 (M4. Cortex-M4 is the owner of reduced power mode control.)
  [5] CM0RSTEN — Cortex-M0+ reset.
    0=DISABLED (Disabled. The Cortex-M0+ is not being reset.); 1=ENABLED (Enabled. The Cortex-M0+ is being reset.)
  [4] CM4RSTEN — Cortex-M4 reset.
    0=DISABLED (Disabled. The Cortex-M4 is not being reset.); 1=ENABLED (Enabled. The Cortex-M4 is being reset.)
  [3] CM0CLKEN — Cortex-M0+ clock enable
    0=DISABLED (Disabled. The Cortex-M0+ clock is not enabled.); 1=ENABLED (Enabled. The Cortex-M0+ clock is enabled.)
  [2] CM4CLKEN — Cortex-M4 clock enable
    0=DISABLED (Disabled. The Cortex-M4 clock is not enabled); 1=ENABLED (Enabled. The Cortex-M4 clock is enabled.)
  [0] MASTERCPU — Indicates which CPU is considered the master. This is factory set assign the Cortex-M4 as the master. The master CPU cannot have its clock turned off via the related CMnCLKEN bit or be reset via the related CMxRSTEN in this register. The slave CPU wakes up briefly following device reset, then goes back to sleep until activated by the master CPU.
    0=M0PL (M0+. Cortex-M0+ is the master CPU.); 1=M4 (M4. Cortex-M4 is the master CPU.)
0x804 CPBOOT — Coprocessor Boot Address
  [31:0] BOOTADDR — Slave processor boot address
0x808 CPSTACK — Coprocessor Stack Address
  [31:0] STACKADDR — Slave processor stack address
0x80C CPSTAT — Coprocessor Status
  [3] CM0LOCKUP ro — When 1, the Cortex-M0+ CPU is in lockup.
  [2] CM4LOCKUP ro — When 1, the Cortex-M4 CPU is in lockup
  [1] CM0SLEEPING ro — When 1, the Cortex-M0+ CPU is sleeping
  [0] CM4SLEEPING ro — When 1, the Cortex-M4 CPU is sleeping
0xFF4 JTAGIDCODE
  [31:0] JTAGID ro — JTAG ID code.
0xFF8 DEVICE_ID0 — Part ID register
  [31:0] PARTID ro
0xFFC DEVICE_ID1 — Boot ROM and die revision register
  [31:0] REVID ro — Revision.
0x20044 BODCTRL — Brown-Out Detect control
  [7] BODINTSTAT — BOD interrupt status. When 1, a BOD interrupt has occurred. Cleared by writing 1 to this bit.
  [6] BODRSTSTAT — BOD reset status. When 1, a BOD reset has occurred. Cleared by writing 1 to this bit.
  [5] BODINTENA — BOD interrupt enable
    0=DISABLE (Disable interrupt function.); 1=ENABLE (Enable interrupt function.)
  [4:3] BODINTLEV — BOD interrupt level
    0=LEVEL0 (Level 0: 2.05 V); 1=LEVEL1 (Level 1: 2.45 V); 2=LEVEL2 (Level 2: 2.75 V); 3=LEVEL3 (Level 3: 3.05 V)
  [2] BODRSTENA — BOD reset enable
    0=DISABLE (Disable reset function.); 1=ENABLE (Enable reset function.)
  [1:0] BODRSTLEV — BOD reset level
    0=LEVEL0 (Level 0: 1.5 V); 1=LEVEL1 (Level 1: 1.85 V); 2=LEVEL2 (Level 2: 2.0 V); 3=LEVEL3 (Level 3: 2.3 V)
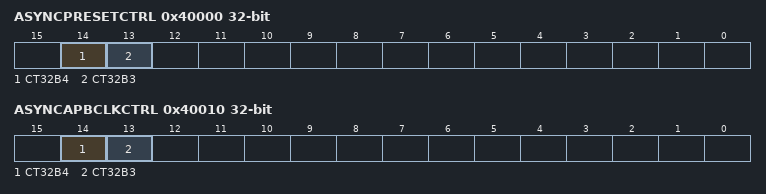
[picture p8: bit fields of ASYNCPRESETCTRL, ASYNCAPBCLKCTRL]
0x40000 ASYNCPRESETCTRL — Async peripheral reset control
  [14] CT32B4 — Standard counter/timer CT32B4 reset control. 0 = Clear reset to this function. 1 = Assert reset to this function.
  [13] CT32B3 — Standard counter/timer CT32B3 reset control. 0 = Clear reset to this function. 1 = Assert reset to this function.
0x40004 ASYNCPRESETCTRLSET reset not defined — Set bits in ASYNCPRESETCTRL
  [31:0] ARST_SET wo — Writing ones to this register sets the corresponding bit or bits in the ASYNCPRESETCTRL register, if they are implemented. Bits that do not correspond to defined bits in ASYNCPRESETCTRL are reserved and only zeroes should be written to them.
0x40008 ASYNCPRESETCTRLCLR reset not defined — Clear bits in ASYNCPRESETCTRL
  [31:0] ARST_CLR wo — Writing ones to this register clears the corresponding bit or bits in the ASYNCPRESETCTRL register, if they are implemented. Bits that do not correspond to defined bits in ASYNCPRESETCTRL are reserved and only zeroes should be written to them.
0x40010 ASYNCAPBCLKCTRL — Async peripheral clock control
  [14] CT32B4 — Controls the clock for CT32B4. 0 = Disable; 1 = Enable.
  [13] CT32B3 — Controls the clock for CT32B3. 0 = Disable; 1 = Enable.
0x40014 ASYNCAPBCLKCTRLSET reset not defined — Set bits in ASYNCAPBCLKCTRL
  [31:0] ACLK_SET wo — Writing ones to this register sets the corresponding bit or bits in the ASYNCAPBCLKCTRL register, if they are implemented. Bits that do not correspond to defined bits in ASYNCPRESETCTRL are reserved and only zeroes should be written to them.
0x40018 ASYNCAPBCLKCTRLCLR reset not defined — Clear bits in ASYNCAPBCLKCTRL
  [31:0] ACLK_CLR wo — Writing ones to this register clears the corresponding bit or bits in the ASYNCAPBCLKCTRL register, if they are implemented. Bits that do not correspond to defined bits in ASYNCAPBCLKCTRL are reserved and only zeroes should be written to them.
0x40020 ASYNCAPBCLKSELA — Async APB clock source select A
  [1:0] SEL — Clock source for asynchronous clock source selector A
    0=MAIN_CLOCK; 1=FRO_12_MHZ
